# RTS5921 register map
Vendor: Realtek Semiconductor Corp.; Series: RTS5921 Series; File version: 0.01
CPU: ARMV8MBL r0p0, little endian, MPU, no FPU, VTOR, 3 interrupt priority bits
Registers are 32-bit, read-write, reset 0x0 unless marked. A register's access mark holds for its fields unless they carry their own. Offsets are from the block's base; [hi:lo] are bit positions; {n}, {i} and the like mark numbered series; 'fields as' and 'values as' point back to an identical list.

## USB_CORE — USB OTG Controller
Base 0x40040000
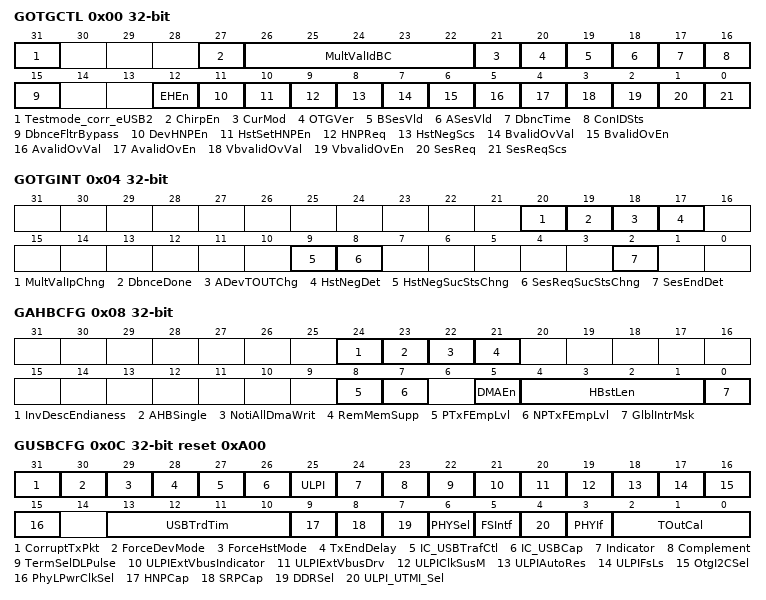
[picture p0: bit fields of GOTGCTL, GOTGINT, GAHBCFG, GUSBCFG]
0x00 GOTGCTL — Control and Status Register
  [31] Testmode_corr_eUSB2 — Correction for eUSB2 PHY during Test mode
  [27] ChirpEn — Core asserting chirp_on before sending an actual Chirp K signal on USB.
  [26:22] MultValIdBC ro — Multi Valued ID pin (MultValIdBC)
  [21] CurMod ro — Current Mode of Operation
  [20] OTGVer — OTG Version
  [19] BSesVld ro — B-session Valid
  [18] ASesVld ro — A-session Valid
  [17] DbncTime ro — Debounce Time
  [16] ConIDSts ro — Connector ID Status
  [15] DbnceFltrBypass — Debounce Filter Bypass
  [12] EHEn — Embedded Host Enable (EHEn)
  [11] DevHNPEn — Device HNP Enabled (DevHNPEn)
  [10] HstSetHNPEn — Host Set HNP Enable (HstSetHNPEn)
  [9] HNPReq — HNP Request (HNPReq)
  [8] HstNegScs ro — Host Negotiation Success (HstNegScs)
  [7] BvalidOvVal — B-Peripheral Session Valid OverrideValue (BvalidOvVal)
  [6] BvalidOvEn — B-Peripheral Session Valid Override Enable
  [5] AvalidOvVal — A-Peripheral Session Valid OverrideValue (AvalidOvVal)
  [4] AvalidOvEn — A-Peripheral Session Valid Override Enable
  [3] VbvalidOvVal — VBUS Valid OverrideValue (VbvalidOvVal)
  [2] VbvalidOvEn — VBUS Valid Override Enable
  [1] SesReq — Session Request
  [0] SesReqScs ro — Session Request Success
0x04 GOTGINT — Interrupt Register
  [20] MultValIpChng — Indicates change in ACA pin value
    0=NO_ACA_PIN_CHANGE (No change in ACA pin value); 1=ACA_PIN_CHANGE (Change in ACA pin value)
  [19] DbnceDone — Debounce Done
    0=INACTIVE (Waiting for debounce completion); 1=ACTIVE (Debounce completed)
  [18] ADevTOUTChg — A-Device Timeout Change
    0=INACTIVE (No A-Device Timeout); 1=ACTIVE (A-Device Timeout)
  [17] HstNegDet — Host Negotiation Detected
    0=INACTIVE (No Active HNP Request); 1=ACTIVE (Active HNP Request Detected)
  [9] HstNegSucStsChng — Host Negotiation Success Status Change
    0=INACTIVE (No Change); 1=ACTIVE (Host Negotiation Status Change)
  [8] SesReqSucStsChng — Session Request Success Status Change
    0=INACTIVE (No Change in Session Request Status); 1=ACTIVE (Session Request Status has changed)
  [2] SesEndDet — Session End Detected
    0=INACTIVE (Session is Active); 1=ACTIVE (Session End signal is deasserted)
0x08 GAHBCFG — AHB Configuration Register
  [24] InvDescEndianess — Invert Descriptor Endianess
    0=DISABLE (Descriptor Endianness is same as AHB Master Endianness); 1=ENABLE (Descriptor Endianness is opposite to AHB Master Endianness)
  [23] AHBSingle — AHB Single Support
    0=INCRBURST (INCR burst size); 1=SINGLEBURST (Single burst size)
  [22] NotiAllDmaWrit — Notify All DMA Write Transactions
    0=LASTTRANS; 1=ALLTRANS
  [21] RemMemSupp — Remote Memory Support
    0=DISABLED; 1=ENABLED
  [8] PTxFEmpLvl — Periodic TxFIFO Empty Level
    0=HALFEMPTY; 1=EMPTY
  [7] NPTxFEmpLvl — Non-Periodic TxFIFO Empty Level
    0=HALFEMPTY; 1=EMPTY
  [5] DMAEn — DMA Enable
    0=SLAVEMODE; 1=DMAMODE
  [4:1] HBstLen — Burst Length/Type
    0=WORD1ORSINGLE; 1=WORD4ORINCR; 2=WORD8; 3=WORD16ORINCR4; 4=WORD32; 5=WORD64ORINCR8; 6=WORD128; 7=WORD256ORINCR16; 8=WORDX (Others reserved)
  [0] GlblIntrMsk — Global Interrupt Mask
    0=MASK (Mask the interrupt assertion to the application); 1=NOMASK (Unmask the interrupt assertion to the application)
0x0C GUSBCFG reset 0xA00 — USB Configuration Register
  [31] CorruptTxPkt — Corrupt Tx packet
    0=NODEBUG (Normal Mode); 1=DEBUG (Debug Mode)
  [30] ForceDevMode — Force Device Mode
    0=DISABLED (Normal Mode); 1=ENABLED (Force Device Mode)
  [29] ForceHstMode — Force Host Mode
    0=DISABLED (Normal Mode); 1=ENABLED (Force Host Mode)
  [28] TxEndDelay
    0=DISABLED (Normal Mode); 1=ENABLED (Tx End delay)
  [27] IC_USBTrafCtl — IC_USB-TrafficPullRemove Control
    0=DISABLED (Not detached during signaling); 1=ENABLED (Detached during signaling)
  [26] IC_USBCap — IC_USB-Capable PHY Interface Selection
    0=NOTSELECTED (PHY Interface not selected); 1=SELECTED (PHY Interface selected)
  [25] ULPI — ULPI Interface Protect Disable
    0=ENABLED (Interface protect circuit enabled); 1=DISABLED (Interface protect circuit disabled)
  [24] Indicator — Indicator Pass Through
    0=QUALIFIED (Qualified with Internal VbusValid); 1=NOTQUALIFIED (Not qualified with Internal VbusValid)
  [23] Complement — Indicator Complement Controls
    0=NONINVERT (Does not invert signal); 1=INVERT (Inverts the signal)
  [22] TermSelDLPulse — TermSel DLine Pulsing Selection
    0=TXVALID (Using utmi_txvalid); 1=TERMSEL (Using utmi_termsel)
  [21] ULPIExtVbusIndicator — ULPI External VBUS Indicator
    0=INTERN (Uses internal VBUS comparator); 1=EXTERN (Uses external VBUS comparator)
  [20] ULPIExtVbusDrv — ULPI External VBUS Drive
    0=INTERN (Drives VBUS with internal charge pump); 1=EXTERN (Drives VBUS using external supply)
  [19] ULPIClkSusM — ULPI Clock SuspendM
    0=PWDCLK (Powers down internal clock during suspend); 1=NONPWDCLK (Does not power down internal clock)
  [18] ULPIAutoRes — ULPI Auto Resume
    0=DISABLED (No AutoResume feature); 1=ENABLED (Uses AutoResume feature)
  [17] ULPIFsLs — ULPI FS/LS Select
    0=DISABLED (ULPI interface selected); 1=ENABLED (ULPI FS/LS serial interface selected)
  [16] OtgI2CSel — UTMIFS or I2C Interface Select
    0=DISABLED (UTMI+ USB 1.1 interface for OTG signals); 1=ENABLED (I2C interface for OTG signals)
  [15] PhyLPwrClkSel — PHY Low-Power Clock Select
    0=INTPLLCLK (480-MHz Internal PLL clock); 1=EXTCLK (48-MHz External Clock)
  [13:10] USBTrdTim — USB Turnaround Time
    9=TURNTIME8BIT (8-bit UTMI+); 5=TURNTIME16BIT (16-bit UTMI+)
  [9] HNPCap — HNP-Capable
    0=DISABLED (HNP not enabled); 1=ENABLED (HNP capability enabled)
  [8] SRPCap — SRP-Capable
    0=DISABLED (SRP capability not enabled); 1=ENABLED (SRP capability enabled)
  [7] DDRSel — ULPI DDR Select
    0=SDR (SDR ULPI Interface); 1=DDR (DDR ULPI Interface)
  [6] PHYSel — PHY Selection
    0=USB20 (Use USB 2.0 high-speed UTMI+ or ULPI PHY); 1=USB11 (USB 1.1 full-speed serial transceiver selected)
  [5] FSIntf — Full-Speed Serial Interface Select
    0=FS6PIN (6-pin unidirectional interface); 1=FS3PIN (3-pin bidirectional interface)
  [4] ULPI_UTMI_Sel — ULPI or UTMI+ Select
    0=UTMI (UTMI+ Interface); 1=ULPI (ULPI Interface)
  [3] PHYIf — PHY Interface
    0=BITS8 (8bit Mode); 1=BITS16 (16bit Mode)
  [2:0] TOutCal — HS/FS Timeout Calibration
    0=ZERO (Add 0 PHY clocks); 1=ONE (Add 1 PHY clocks); 2=TWO (Add 2 PHY clocks); 3=THREE (Add 3 PHY clocks); 4=FOUR (Add 4 PHY clocks); 5=FIVE (Add 5 PHY clocks); 6=SIX (Add 6 PHY clocks); 7=SEVEN (Add 7 PHY clocks)
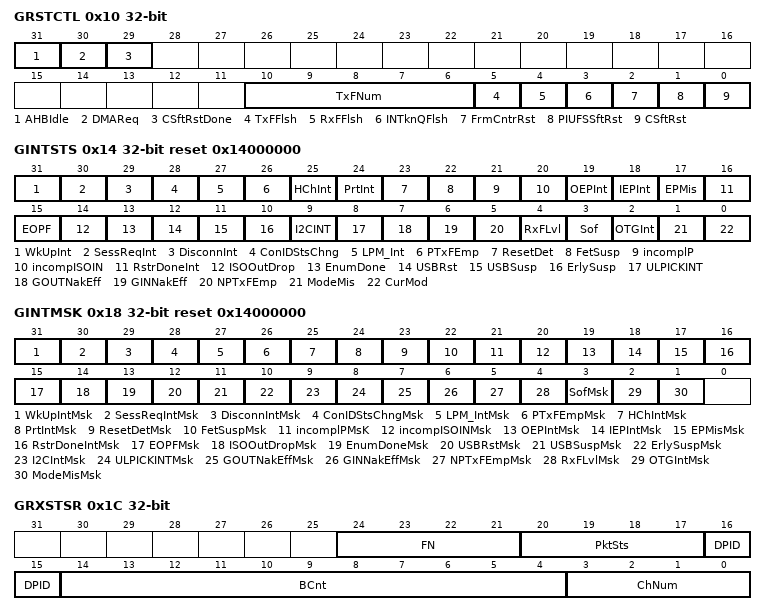
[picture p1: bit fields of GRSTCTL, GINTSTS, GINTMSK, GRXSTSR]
0x10 GRSTCTL — Reset Register
  [31] AHBIdle ro — AHB Master Idle
    0=INACTIVE (Not Idle); 1=ACTIVE (AHB Master Idle)
  [30] DMAReq ro — DMA Request Signal
    0=INACTIVE (No DMA request); 1=ACTIVE (DMA request in progress)
  [29] CSftRstDone — Core Soft Reset Done
    0=INACTIVE (No reset); 1=ACTIVE (Core Soft Reset is done)
  [10:6] TxFNum — TxFIFO Number
    0=TXF0 (Periodic TxFIFO 0 Flush); 1=TXF1 (Periodic TxFIFO 1 Flush); 2=TXF2 (Periodic TxFIFO 2 Flush); 16=TXF16 (Flush all Tx FIFOs)
  [5] TxFFlsh — TxFIFO Flush
    0=INACTIVE (No Flush); 1=ACTIVE (Flushes TxFIFOs)
  [4] RxFFlsh — RxFIFO Flush
    0=INACTIVE (Does not flush RxFIFO); 1=ACTIVE (Flushes entire RxFIFO)
  [3] INTknQFlsh — IN Token Queue Flush
    0=INACTIVE (No Flush); 1=ACTIVE (Flush IN Token Queue)
  [2] FrmCntrRst — Host Frame Counter Reset
    0=NOTACTIVE (No reset); 1=ACTIVE (Reset Frame Counter)
  [1] PIUFSSftRst — PIU FS Soft Reset
    0=RESET_INACTIVE (No Reset); 1=RESET_ACTIVE (PIU FS Soft Reset)
  [0] CSftRst — Core Soft Reset
    0=NOTACTIVE (No reset); 1=ACTIVE (Reset both hclk and phy_clock domains)
0x14 GINTSTS reset 0x14000000 — Interrupt Register
  [31] WkUpInt — Resume/Remote Wakeup Detected Interrupt
    0=INACTIVE (Not active); 1=ACTIVE (Resume/Remote Wakeup Detected)
  [30] SessReqInt — Session Request/New Session Detected Interrupt
    0=INACTIVE (Not active); 1=ACTIVE (Session Request/New Session Detected)
  [29] DisconnInt — Disconnect Detected Interrupt
    0=INACTIVE (Not active); 1=ACTIVE (Disconnect Detected)
  [28] ConIDStsChng — Connector ID Status Change
    0=INACTIVE (Not active); 1=ACTIVE (Connector ID Status Change)
  [27] LPM_Int — LPM Transaction Received Interrupt
    0=INACTIVE (Not active); 1=ACTIVE (LPM Transaction Received)
  [26] PTxFEmp ro — Periodic TxFIFO Empty
    0=INACTIVE (Not active); 1=ACTIVE (Periodic TxFIFO Empty)
  [25] HChInt ro — Host Channels Interrupt
    0=INACTIVE (Not active); 1=ACTIVE (Host Channels Interrupt)
  [24] PrtInt ro — Host Port Interrupt
    0=INACTIVE (Not active); 1=ACTIVE (Host Port Interrupt)
  [23] ResetDet — Reset Detected Interrupt
    0=INACTIVE (Not active); 1=ACTIVE (Reset Detected)
  [22] FetSusp — Data Fetch Suspended
    0=INACTIVE (Not active); 1=ACTIVE (Data Fetch Suspended)
  [21] incomplP — Incomplete Periodic Transfer
    0=INACTIVE (Not active); 1=ACTIVE (Incomplete Periodic Transfer)
  [20] incompISOIN — Incomplete Isochronous IN Transfer
    0=INACTIVE (Not active); 1=ACTIVE (Incomplete Isochronous IN Transfer)
  [19] OEPInt ro — OUT Endpoints Interrupt
    0=INACTIVE (Not active); 1=ACTIVE (OUT Endpoints Interrupt)
  [18] IEPInt ro — IN Endpoints Interrupt
    0=INACTIVE (Not active); 1=ACTIVE (IN Endpoints Interrupt)
  [17] EPMis — Endpoint Mismatch Interrupt
    0=INACTIVE (Not active); 1=ACTIVE (Endpoint Mismatch Interrupt)
  [16] RstrDoneInt — Restore Done Interrupt
    0=INACTIVE (Not active); 1=ACTIVE (Restore Done Interrupt)
  [15] EOPF — End of Periodic Frame Interrupt
    0=INACTIVE (Not active); 1=ACTIVE (End of Periodic Frame Interrupt)
  [14] ISOOutDrop — Isochronous OUT Packet Dropped Interrupt
    0=INACTIVE (Not active); 1=ACTIVE (Isochronous OUT Packet Dropped)
  [13] EnumDone — Enumeration Done
    0=INACTIVE (Not active); 1=ACTIVE (Enumeration Done)
  [12] USBRst — USB Reset
    0=INACTIVE (Not active); 1=ACTIVE (USB Reset)
  [11] USBSusp — USB Suspend
    0=INACTIVE (Not active); 1=ACTIVE (USB Suspend)
  [10] ErlySusp — Early Suspend
    0=INACTIVE (No Idle state detected); 1=ACTIVE (3ms of Idle state detected)
  [9] I2CINT — I2C Interrupt
    0=INACTIVE (Not Active); 1=ACTIVE (I2C Interrupt)
  [8] ULPICKINT — ULPI Carkit Interrupt
    0=INACTIVE (Not Active); 1=ACTIVE (Interrupt is asserted high when ULPI Carkit Interrupt is received)
  [7] GOUTNakEff ro — Global OUT NAK Effective
    0=INACTIVE (Not Active); 1=ACTIVE (Global OUT NAK Effective)
  [6] GINNakEff ro — Global IN Non-periodic NAK Effective
    0=INACTIVE (Global Non-periodic IN NAK not active); 1=ACTIVE (Set Global Non-periodic IN NAK bit)
  [5] NPTxFEmp ro — Non-periodic TxFIFO Empty
    0=INACTIVE (Non-periodic TxFIFO is not empty); 1=ACTIVE (Non-periodic TxFIFO is empty)
  [4] RxFLvl ro — RxFIFO Non-Empty
    0=INACTIVE (RxFIFO is empty); 1=ACTIVE (RxFIFO is not empty)
  [3] Sof — Start of (micro)Frame
    0=INACTIVE (No Start of Frame); 1=ACTIVE (Start of Frame)
  [2] OTGInt ro — OTG Interrupt
    0=INACTIVE (No Interrupt); 1=ACTIVE (OTG Interrupt)
  [1] ModeMis — Mode Mismatch Interrupt
    0=INACTIVE (No Mode Mismatch Interrupt); 1=ACTIVE (Mode Mismatch Interrupt)
  [0] CurMod ro — Current Mode of Operation
    0=DEVICE (Device mode); 1=HOST (Host mode)
0x18 GINTMSK reset 0x14000000 — Interrupt Mask Register
  [31] WkUpIntMsk — Resume/Remote Wakeup Detected Interrupt Mask
    0=MASK (Mask Resume/Remote Wakeup Detected Interrupt); 1=NOMASK (Unmask Resume/Remote Wakeup Detected Interrupt)
  [30] SessReqIntMsk — Session Request/New Session Detected Interrupt Mask
    0=MASK (Mask Session Request/New Session Detected Interrupt); 1=NOMASK (Unmask Session Request/New Session Detected Interrupt)
  [29] DisconnIntMsk — Disconnect Detected Interrupt Mask
    0=MASK (Mask Disconnect Detected Interrupt); 1=NOMASK (Unmask Disconnect Detected Interrupt)
  [28] ConIDStsChngMsk — Connector ID Status Change Mask
    0=MASK (Mask Connector ID Status Change Interrupt); 1=NOMASK (Unmask Connector ID Status Change Interrupt)
  [27] LPM_IntMsk — LPM Transaction Received Interrupt Mask
    0=MASK (Mask LPM Transaction Received Interrupt); 1=NOMASK (Unmask LPM Transaction Received Interrupt)
  [26] PTxFEmpMsk — Periodic TxFIFO Empty Mask, Host only
    0=MASK (Mask Periodic TxFIFO Empty Interrupt); 1=NOMASK (Unmask Periodic TxFIFO Empty Interrupt)
  [25] HChIntMsk — Host Channels Interrupt Mask, Host only
    0=MASK (Mask Host Channels Interrupt); 1=NOMASK (Unmask Host Channels Interrupt)
  [24] PrtIntMsk — Host Port Interrupt Mask, Host only
    0=MASK (Mask Host Port Interrupt); 1=NOMASK (Unmask Host Port Interrupt)
  [23] ResetDetMsk — Reset Detected Interrupt Mask, Device only
    0=MASK (Mask Reset Detected Interrupt); 1=NOMASK (Unmask Reset Detected Interrupt)
  [22] FetSuspMsk — Data Fetch Suspended Mask, Device only
    0=MASK (Mask Data Fetch Suspended Interrupt); 1=NOMASK (Unmask Data Fetch Suspended Interrupt)
  [21] incomplPMsK — Incomplete Periodic Transfer Mask, Host only
    0=MASK (Mask Incomplete Periodic Transfer Interrupt); 1=NOMASK (Unmask Incomplete Periodic Transfer Interrupt)
  [20] incompISOINMsk — Incomplete Isochronous IN Transfer Mask, Device only
    0=MASK (Mask Incomplete Isochronous IN Transfer Interrupt); 1=NOMASK (Unmask Incomplete Isochronous IN Transfer Interrupt)
  [19] OEPIntMsk — OUT Endpoints Interrupt Mask, Device only
    0=MASK (Mask OUT Endpoints Interrupt); 1=NOMASK (Unmask OUT Endpoints Interrupt)
  [18] IEPIntMsk — IN Endpoints Interrupt Mask, Device only
    0=MASK (Mask IN Endpoints Interrupt); 1=NOMASK (Unmask IN Endpoints Interrupt)
  [17] EPMisMsk — Endpoint Mismatch Interrupt Mask, Device only
    0=MASK (Mask Endpoint Mismatch Interrupt); 1=NOMASK (Unmask Endpoint Mismatch Interrupt)
  [16] RstrDoneIntMsk — Restore Done Interrupt Mask
    0=MASK (Mask Restore Done Interrupt); 1=NOMASK (Unmask Restore Done Interrupt)
  [15] EOPFMsk — End of Periodic Frame Interrupt Mask, Device only
    0=MASK (Mask End of Periodic Frame Interrupt); 1=NOMASK (Unmask End of Periodic Frame Interrupt)
  [14] ISOOutDropMsk — Isochronous OUT Packet Dropped Interrupt Mask, Device only
    0=MASK (Mask Isochronous OUT Packet Dropped Interrupt); 1=NOMASK (Unmask Isochronous OUT Packet Dropped Interrupt)
  [13] EnumDoneMsk — Enumeration Done Mask, Device only
    0=MASK (Mask Enumeration Done Interrupt); 1=NOMASK (Unmask Enumeration Done Interrupt)
  [12] USBRstMsk — USB Reset Mask, Device only
    0=MASK (Mask USB Reset Interrupt); 1=NOMASK (Unmask USB Reset Interrupt)
  [11] USBSuspMsk — USB Suspend Mask, Device only
    0=MASK (Mask USB Suspend Interrupt); 1=NOMASK (Unmask USB Suspend Interrupt)
  [10] ErlySuspMsk — Early Suspend Mask, Device only
    0=MASK (Mask Early Suspend Interrupt); 1=NOMASK (Unmask Early Suspend Interrupt)
  [9] I2CIntMsk — I2C Interrupt Mask
    0=MASK (Mask I2C Interrupt); 1=NOMASK (Unmask I2C Interrupt)
  [8] ULPICKINTMsk — ULPI Carkit Interrupt Mask
    0=MASK (Mask ULPI Carkit Interrupt); 1=NOMASK (Unmask ULPI Carkit Interrupt)
  [7] GOUTNakEffMsk — Global OUT NAK Effective Mask, Device only
    0=MASK (Mask Global OUT NAK Effective Interrupt); 1=NOMASK (Unmask Global OUT NAK Effective Interrupt)
  [6] GINNakEffMsk — Global Non-periodic IN NAK Effective Mask, Device only
    0=MASK (Mask Global Non-periodic IN NAK Effective Interrupt); 1=NOMASK (Unmask Global Non-periodic IN NAK Effective Interrupt)
  [5] NPTxFEmpMsk — Non-periodic TxFIFO Empty Mask
    0=MASK (Mask Non-periodic TxFIFO Empty Interrupt); 1=NOMASK (Unmask Non-periodic TxFIFO Empty Interrupt)
  [4] RxFLvlMsk — Receive FIFO Non-Empty Mask
    0=MASK (Mask Receive FIFO Non-Empty Interrupt); 1=NOMASK (Unmask Receive FIFO Non-Empty Interrupt)
  [3] SofMsk — Start of Frame Mask
    0=MASK (Mask Start of Frame Interrupt); 1=NOMASK (Unmask Start of Frame Interrupt)
  [2] OTGIntMsk — OTG Interrupt Mask
    0=MASK (Mask OTG Interrupt); 1=NOMASK (Unmask OTG Interrupt)
  [1] ModeMisMsk — Mode Mismatch Interrupt Mask
    0=MASK (Mask Mode Mismatch Interrupt); 1=NOMASK (Unmask Mode Mismatch Interrupt)
0x1C GRXSTSR ro — Receive Status Debug Read Register
  [24:21] FN — Frame Number (Device only)
  [20:17] PktSts — Packet Status
    1=OUTNAK (Global OUT NAK in device mode); 2=INOUTDPRX (IN/OUT data packet received); 3=INOUTTRCOM (IN or OUT transfer completed); 4=DSETUPCOM (SETUP transaction completed); 5=DTTOG (Data toggle error); 6=DSETUPRX (SETUP data packet received); 7=CHHALT (Channel halted)
  [16:15] DPID — Data PID
    0=DATA0 (DATA0 packet); 2=DATA1 (DATA1 packet); 1=DATA2 (DATA2 packet); 3=MDATA (MDATA packet)
  [14:4] BCnt — Byte Count
  [3:0] ChNum — Channel Number / Endpoint Number
    {v}=CHEP{v} (Channel or Endpoint {v}) (v=0..15)
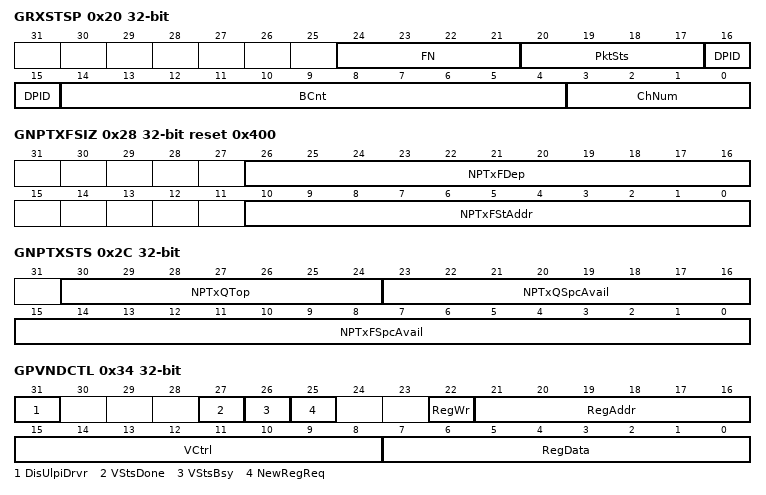
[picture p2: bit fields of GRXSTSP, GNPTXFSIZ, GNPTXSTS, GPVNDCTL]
0x20 GRXSTSP ro — Receive Status Read/Pop Register
  fields as GRXSTSR
0x24 GRXFSIZ reset 0x200 — Receive FIFO Size Register
0x28 GNPTXFSIZ reset 0x400 — Non-periodic Transmit FIFO Size Register
  [26:16] NPTxFDep — Non-periodic TxFIFO Depth
  [10:0] NPTxFStAddr — Non-periodic Transmit RAM Start Address
0x2C GNPTXSTS ro — Non-periodic Transmit FIFO/Queue Status Register
  [30:24] NPTxQTop — Top of the Non-periodic Transmit Request Queue
  [23:16] NPTxQSpcAvail — Non-periodic Transmit Request Queue Space Available
  [15:0] NPTxFSpcAvail — Non-periodic TxFIFO Space Available
0x30 GI2CCTL — I2C Access Register
0x34 GPVNDCTL — PHY Vendor Control Register
  [31] DisUlpiDrvr — Disable ULPI Drivers
    0=ENABLED (Enable ULPI output signals); 1=DISABLED (Disable ULPI output signals)
  [27] VStsDone — VStatus Done
    0=INACTIVE (VStatus Done inactive); 1=ACTIVE (VStatus Done active)
  [26] VStsBsy ro — VStatus Busy
    0=INACTIVE (VStatus Busy inactive); 1=ACTIVE (VStatus Busy active)
  [25] NewRegReq — New Register Request
    0=INACTIVE (New Register Request not active); 1=ACTIVE (New Register Request active)
  [22] RegWr — Register Write
    0=READ; 1=WRITE
  [21:16] RegAddr — Register Address
  [15:8] VCtrl — UTMI+ Vendor Control Register Address
  [7:0] RegData — Register Data
0x38 GGPIO — General Purpose Input/Output Register
0x3C GUID — User ID Register
0x40 GSNPSID ro — Synopsys ID Register
0x44 GHWCFG1 ro — User Hardware Configuration 1 Register
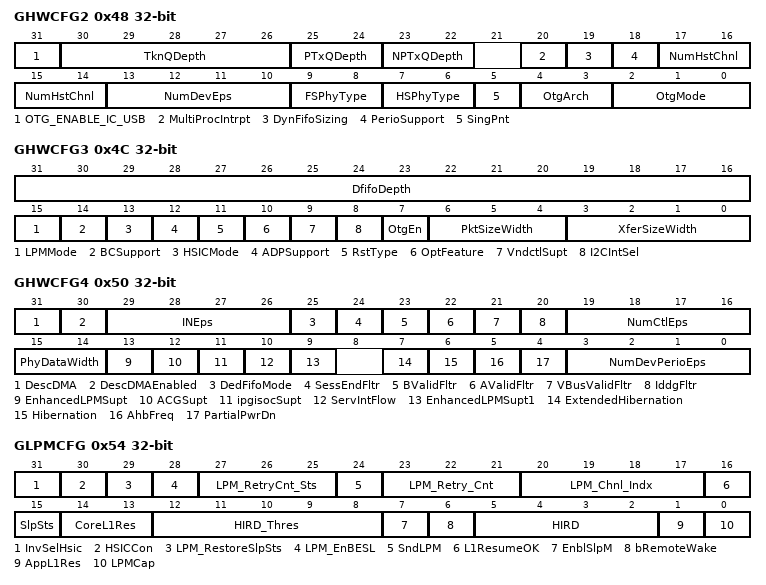
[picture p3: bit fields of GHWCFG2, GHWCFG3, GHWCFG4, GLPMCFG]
0x48 GHWCFG2 ro — User Hardware Configuration 2 Register
  [31] OTG_ENABLE_IC_USB — IC_USB mode specified for mode of operation
    0=DISABLE (Disabled the IC_USB Full-Speed Serial Transceiver interface); 1=ENABLE (Enabled the IC_USB Full-Speed Serial Transceiver interface)
  [30:26] TknQDepth — Device Mode IN Token Sequence Learning Queue Depth
  [25:24] PTxQDepth — Host Mode Periodic Request Queue Depth
    0=QUE2 (Queue Depth 2); 1=QUE4 (Queue Depth 4); 2=QUE8 (Queue Depth 8); 3=QUE16 (Queue Depth 16)
  [23:22] NPTxQDepth — Non-periodic Request Queue Depth
    0=TWO (Queue size 2); 1=FOUR (Queue size 4); 2=EIGHT (Queue size 8)
  [20] MultiProcIntrpt — Multi Processor Interrupt Enabled
    0=DISABLED (No Multi Processor Interrupt Enabled); 1=ENABLED (Multi Processor Interrupt Enabled)
  [19] DynFifoSizing — Dynamic FIFO Sizing Enabled
    0=DISABLED (Dynamic FIFO Sizing Disabled); 1=ENABLED (Dynamic FIFO Sizing Enabled)
  [18] PerioSupport — Periodic OUT Channels Supported in Host Mode
    0=DISABLED (Periodic OUT Channels is not supported in Host Mode); 1=ENABLED (Periodic OUT Channels Supported in Host Mode Supported)
  [17:14] NumHstChnl — Number of Host Channels
    {v}=HOSTCH{v} (Host Channel {v+1}) (v=0..15)
  [13:10] NumDevEps — Number of Device Endpoints
    {v}=ENDPT{v} (End point {v}) (v=0..15)
  [9:8] FSPhyType — Full-Speed PHY Interface Type
    0=NO_FS (Full-speed interface not supported); 1=FS (Dedicated full-speed interface is supported); 2=FSPLUSUTMI (FS pins shared with UTMI+ pins is supported); 3=FSPLUSULPI (FS pins shared with ULPI pins is supported)
  [7:6] HSPhyType — High-Speed PHY Interface Type
    0=NOHS (High-Speed interface not supported); 1=UTMIPLUS (High Speed Interface UTMI+ is supported); 2=ULPI (High Speed Interface ULPI is supported); 3=UTMIPUSULPI (High Speed Interfaces UTMI+ and ULPI is supported)
  [5] SingPnt — Point-to-Point
    0=MULTIPOINT (Multi-point application (hub and split support)); 1=SINGLEPOINT (Single-point application (no hub and split support))
  [4:3] OtgArch — Architecture
    0=SLAVEMODE; 1=EXTERNALDMA (External DMA Mode); 2=INTERNALDMA (Internal DMA Mode)
  [2:0] OtgMode — Mode of Operation
    0=HNPSRP (HNP- and SRP-Capable OTG (Host and Device)); 1=SRPOTG (SRP-Capable OTG (Host and Device)); 2=NHNPNSRP (Non-HNP and Non-SRP Capable OTG (Host and Device)); 3=SRPCAPD (SRP-Capable Device); 4=NONOTGD (Non-OTG Device); 5=SRPCAPH (SRP-Capable Host); 6=NONOTGH (Non-OTG Host)
0x4C GHWCFG3 ro — User Hardware Configuration 3 Register
  [31:16] DfifoDepth
  [15] LPMMode
    0=DISABLED (LPM disabled); 1=ENABLED (LPM enabled)
  [14] BCSupport — Battery Charger Support
    0=DISABLED (No Battery Charger Support); 1=ENABLED (Battery Charger Support present)
  [13] HSICMode
    0=DISABLED (No HSIC capability); 1=ENABLED (HSIC-capable with shared UTMI PHY)
  [12] ADPSupport — ADP Logic Support
    0=DISABLED (ADP logic is not present); 1=ENABLED (ADP logic is present)
  [11] RstType — Reset Style for Clocked Blocks
    0=ASYNCRST (Asynchronous reset is used); 1=SYNCRST (Synchronous reset is used)
  [10] OptFeature — Optional Features Removed
    0=DISABLED (Optional features not removed); 1=ENABLED (Optional features removed)
  [9] VndctlSupt — Vendor Control Interface Support
    0=DISABLED (Vendor Control Interface not available); 1=ENABLED (Vendor Control Interface available)
  [8] I2CIntSel — I2C Interface Selection
    0=DISABLED (I2C Interface not available); 1=ENABLED (I2C Interface available)
  [7] OtgEn — OTG Function Enabled
    0=DISABLED (Not OTG Capable); 1=ENABLED (OTG Capable)
  [6:4] PktSizeWidth — Width of Packet Size Counters
    {v}=BITS{v+4} (Width of Packet Size Counter {v+4}) (v=0..6)
  [3:0] XferSizeWidth — Width of Transfer Size Counters
    {v}=WIDTH{v+11} (Width of Transfer Size Counter {v+11} bits) (v=0..8)
0x50 GHWCFG4 ro — User Hardware Configuration 4 Register
  [31] DescDMA — Scatter/Gather DMA configuration
    0=CONFIG1 (Non-Dynamic configuration); 1=CONFIG2 (Dynamic configuration)
  [30] DescDMAEnabled — Scatter/Gather DMA configuration enabled
    0=DISABLE (Non-Scatter/Gather DMA configuration); 1=ENABLE (Scatter/Gather DMA configuration)
  [29:26] INEps — Number of Device Mode IN Endpoints Including Control Endpoints
    0=ENDPT1 (1 IN Endpoint); 1=ENDPT2 (2 IN Endpoints); 15=ENDPT16 (16 IN Endpoints)
  [25] DedFifoMode — Enable Dedicated Transmit FIFO for device IN Endpoints
    0=DISABLED (Dedicated Transmit FIFO Operation not enabled); 1=ENABLED (Dedicated Transmit FIFO Operation enabled)
  [24] SessEndFltr — Session end filter enabled
    0=DISABLED (No filter); 1=ENABLED (Filter enabled)
  [23] BValidFltr — b_valid filter enabled
    0=DISABLED (No Filter); 1=ENABLED (Filter enabled)
  [22] AValidFltr — a_valid filter enabled
    0=DISABLED (No filter); 1=ENABLED (Filter enabled)
  [21] VBusValidFltr — VBUS Valid Filter Enabled
    0=DISABLED (Vbus Valid Filter Disabled); 1=ENABLED (Vbus Valid Filter Enabled)
  [20] IddgFltr — IDDIG Filter Enabled
    0=DISABLED (Iddig Filter Disabled); 1=ENABLED (Iddig Filter Enabled)
  [19:16] NumCtlEps — Number of Device Mode Control Endpoints in Addition to Endpoint 0
    0=ENDPT0 (End point 0); 1=ENDPT1 (End point 1); 15=ENDPT15 (End point 15)
  [15:14] PhyDataWidth — UTMI+ PHY/ULPI-to-Internal UTMI+ Wrapper Data Width
    0=WIDTH1 (8 bits); 1=WIDTH2 (16 bits); 2=WIDTH3 (8/16 bits, software selectable)
  [13] EnhancedLPMSupt — Enhanced LPM Support
    0=DISABLED (Enhanced LPM Support is Disabled); 1=ENABLED (Enhanced LPM Support is enabled)
  [12] ACGSupt — Active Clock Gating Support
    0=DISABLED (Active Clock Gating Support disabled); 1=ENABLED (Active Clock Gating Support enabled)
  [11] ipgisocSupt — Interpacket Gap ISOC OUT Worst-case Support
    0=DISABLED (Interpacket Gap ISOC OUT Worst-case Support is Disabled); 1=ENABLED (Interpacket Gap ISOC OUT Worst-case Support is Enabled)
  [10] ServIntFlow — Service Interval Flow
    0=DISABLED (Service Interval Flow not supported); 1=ENABLED (Service Interval Flow supported)
  [9] EnhancedLPMSupt1 — Enhanced LPM Support1
    0=DISABLED (Reject L1 Request if Non-Periodic TxFIFO is not empty); 1=ENABLED (Accept L1 Request even if Non-Periodic TxFIFO not empty)
  [7] ExtendedHibernation — Enable Hibernation
    0=DISABLED (Extended Hibernation feature not enabled); 1=ENABLED (Extended Hibernation feature enabled)
  [6] Hibernation — Enable Hibernation
    0=DISABLED (Hibernation feature disabled); 1=ENABLED (Hibernation feature enabled)
  [5] AhbFreq — Minimum AHB Frequency Less Than 60 MHz
    0=DISABLED (Minimum AHB Frequency More Than 60 MHz); 1=ENABLED (Minimum AHB Frequency Less Than 60 MHz)
  [4] PartialPwrDn — Enable Partial Power Down
    0=DISABLED (Partial Power Down disabled); 1=ENABLED (Partial Power Down enabled)
  [3:0] NumDevPerioEps — Number of Device Mode Periodic IN Endpoints
    0=Number of Periodic IN EPs is 0; 1=Number of Periodic IN EPs is 1; 15=Number of Periodic IN EPs is 15
0x54 GLPMCFG — LPM Config Register
  [31] InvSelHsic — HSIC-Invert Select HSIC
    0=HSIC capability enabled if if_sel_hsic=1; 1=HSIC capability enabled if if_sel_hsic=0
  [30] HSICCon — HSIC-Connect
    0=DISABLE_HSIC_CONNECT (Core does not initiate HSIC connect); 1=ENABLE_HSIC_CONNECT (Core initiates the HSIC connect)
  [29] LPM_RestoreSlpSts — LPM Restore Sleep Status
    0=DISABLED (Shallow Sleep mode based on BESL value); 1=ENABLED (Deep Sleep mode based on BESL value)
  [28] LPM_EnBESL — LPM Enable BESL
    0=DISABLED (BESL is disabled); 1=ENABLED (BESL is enabled)
  [27:25] LPM_RetryCnt_Sts ro — LPM Retry Count Status
    0=RETRY_REM0 (Zero LPM retries remaining); 1=RETRY_REM1 (One LPM retry remaining); 2=RETRY_REM2 (Two LPM retries remaining); 3=RETRY_REM3 (Three LPM retries remaining); 4=RETRY_REM4 (Four LPM retries remaining); 5=RETRY_REM5 (Five LPM retries remaining); 6=RETRY_REM6 (Six LPM retries remaining); 7=RETRY_REM7 (Seven LPM retries remaining)
  [24] SndLPM — Send LPM Transaction
    0=DISABLED (Received the response from device); 1=ENABLED (Sending LPM transaction)
  [23:21] LPM_Retry_Cnt — LPM Retry Count
    0=RETRY0 (Zero LPM retries); 1=RETRY1 (One LPM retry); 2=RETRY2 (Two LPM retries); 3=RETRY3 (Three LPM retries); 4=RETRY4 (Four LPM retries); 5=RETRY5 (Five LPM retries); 6=RETRY6 (Six LPM retries); 7=RETRY7 (Seven LPM retries)
  [20:17] LPM_Chnl_Indx — LPM Channel Index
    {v}=CH{v} (Channel {v}) (v=0..15)
  [16] L1ResumeOK — Sleep State Resume OK
    0=NOTOK (Cannot start Resume from Sleep state); 1=OK (Can start Resume from Sleep state)
  [15] SlpSts — Port Sleep Status
    0=CORE_NOT_IN_L1 (Core is not in L1); 1=CORE_IN_L1 (Core transitions to Sleep state)
  [14:13] CoreL1Res — LPM Response
    0=LPMRESP1 (No handshake response); 1=LPMRESP2 (STALL response); 2=LPMRESP3 (NYET response); 3=LPMRESP4 (ACK response)
  [12:8] HIRD_Thres — BESL/HIRD Threshold
  [7] EnblSlpM — Enable utmi_sleep_n
    0=DISABLED (utmi_sleep_n assertion not transferred); 1=ENABLED (utmi_sleep_n assertion transferred)
  [6] bRemoteWake — RemoteWakeEnable
    0=DISABLED (Remote Wakeup is disabled); 1=ENABLED (Remote Wakeup enabled)
  [5:2] HIRD — Host-Initiated Resume Duration
  [1] AppL1Res — LPM response programmed by application
    0=NYET_RESP (Respond with NYET on error detection); 1=ACK_RESP (Respond with ACK on successful LPM transaction)
  [0] LPMCap — LPM-Capable
    0=DISABLED (LPM capability not enabled); 1=ENABLED (LPM capability enabled)
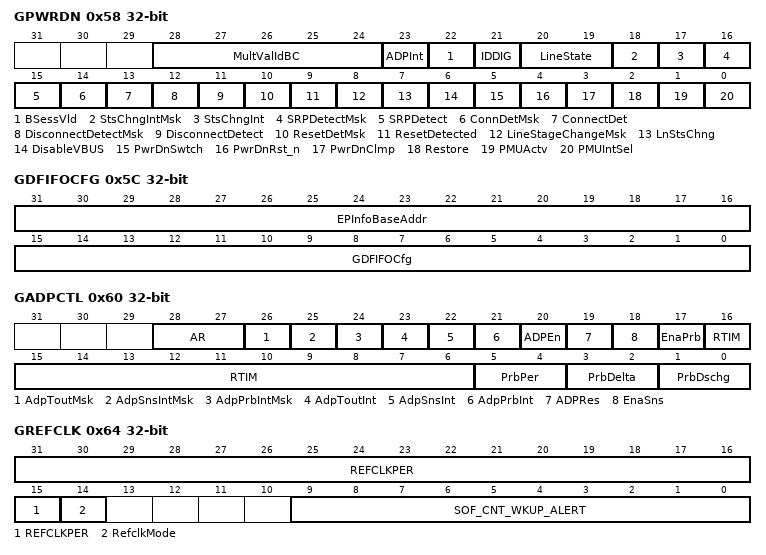
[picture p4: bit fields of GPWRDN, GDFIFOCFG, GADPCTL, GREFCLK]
0x58 GPWRDN — Global Power Down Register
  [28:24] MultValIdBC
    0=RID_0 (OTG device as B-device); 1=RID_C (OTG device as B-device, can connect); 2=RID_B (OTG device as B-device, cannot connect); 4=RID_A (OTG device as A-device); 8=RID_GND (ID_OTG pin is grounded); 16=RID_FLOAT (ID pull down when ID_OTG is floating); 17=RID_C_RID_FLOAT (OTG device as B-device, can connect, RID_C=1 and RID_FLOAT=1); 18=RID_B_RID_FLOAT (OTG device as B-device, cannot connect, RID_B=1 and RID_FLOAT=1); 12=RID_A_RID_GND (OTG device as A-device, RID_A=1 and RID_GND=1); 31=RID_1 (OTG device as A-device)
  [23] ADPInt — ADP Interrupt
    0=DISABLED (No ADP Event Interrupt); 1=ENABLED (ADP Event Interrupt)
  [22] BSessVld ro — B Session Valid
    0=NOTVALID (B_Valid is 0); 1=VALID (B_Valid is 1)
  [21] IDDIG ro — Status of signal IDDIG
    0=DISABLED (Host Mode); 1=ENABLED (Device Mode)
  [20:19] LineState ro
    0=LS1 (Linestate on USB: DM = 0, DP = 0); 1=LS2 (Linestate on USB: DM = 0, DP = 1); 2=LS3 (Linestate on USB: DM = 1, DP = 0); 3=LS4 (Linestate on USB: Not-defined)
  [18] StsChngIntMsk — Status Change Interrupt Mask
    0=NOMASK (No Status Change Interrupt Mask); 1=MASK (Mask for Status Change Interrupt)
  [17] StsChngInt — Status Change Interrupt
    0=DISABLED (No Status change); 1=ENABLED (Status change detected)
  [16] SRPDetectMsk — SRP Detect Mask
    0=NOMASK (No SRPDetect Interrupt Mask); 1=MASK (Mask for SRPDetect Interrupt)
  [15] SRPDetect
    0=DISABLED (SRP not detected); 1=ENABLED (SRP detected)
  [14] ConnDetMsk — Connect Detect Mask
    0=NOMASK (No ConnectDet Interrupt Mask); 1=MASK (Mask for ConnectDet Interrupt)
  [13] ConnectDet — Connect Detect
    0=DISABLED (Connect not detected); 1=ENABLED (Connect detected)
  [12] DisconnectDetectMsk — Disconnect Detect Mask
    0=NOMASK (No DisconnectDetect Interrupt Mask); 1=MASK (Mask for DisconnectDetect Interrupt)
  [11] DisconnectDetect
    0=DISABLED (Disconnect not detected); 1=ENABLED (Disconnect detected)
  [10] ResetDetMsk — Reset Detect Mask
    0=NOMASK (No ResetDetect Interrupt Mask); 1=MASK (Mask for ResetDetect Interrupt)
  [9] ResetDetected
    0=DISABLED (Reset not detected); 1=ENABLED (Reset detected)
  [8] LineStageChangeMsk — Line State Change Mask
    0=NOMASK (No LineStateChange Interrupt Mask); 1=MASK (Mask for LineStateChange Interrupt)
  [7] LnStsChng — Line State Change
    0=DISABLED (No LineState change on USB); 1=ENABLED (LineState change on USB)
  [6] DisableVBUS
    0=DISABLED (Not programmed to disable VBUS); 1=ENABLED (Programmed to disable VBUS)
  [5] PwrDnSwtch — Power Down Switch
    0=ON (The controller is in ON state); 1=OFF (The controller is in OFF state)
  [4] PwrDnRst_n — Power Down ResetN
    0=DISABLE (Reset the controller); 1=ENABLE (Normal operation)
  [3] PwrDnClmp — Power Down Clamp
    0=DISABLE (Disable PMU power clamp); 1=ENABLE (Enable PMU power clamp)
  [2] Restore
    0=DISABLE (Normal mode of operation); 1=ENABLE (Restore mode)
  [1] PMUActv — PMU Active
    0=DISABLE (Disable PMU module); 1=ENABLE (Enable PMU module)
  [0] PMUIntSel — PMU Interrupt Select
    0=DISABLE (Internal DWC_otg_core interrupt); 1=ENABLE (External DWC_otg_pmu interrupt)
0x5C GDFIFOCFG — Global DFIFO Configuration Register
  [31:16] EPInfoBaseAddr — Start address of the EP info controller
  [15:0] GDFIFOCfg — GDFIFO Configuration
0x60 GADPCTL — ADP Timer, Control and Status Register
  [28:27] AR — Access Request
    0=Request1 (Read/Write); 1=Request2 (Read); 2=Request3 (Write)
  [26] AdpToutMsk — ADP Timeout Interrupt Mask
    0=MASK (Mask ADP Timeout Interrupt); 1=NOMASK (Unmask ADP Timeout Interrupt)
  [25] AdpSnsIntMsk — ADP Sense Interrupt Mask
    0=MASK (Mask ADP Sense Interrupt); 1=NOMASK (Unmask ADP Sense Interrupt)
  [24] AdpPrbIntMsk — ADP Probe Interrupt Mask
    0=MASK (Mask ADP Probe Interrupt); 1=NOMASK (Unmask ADP Probe Interrupt)
  [23] AdpToutInt — ADP Timeout Interrupt
    0=NOTACTIVE; 1=ACTIVE (ADP Timeout Interrupt)
  [22] AdpSnsInt — ADP Sense Interrupt
    0=NOTACTIVE; 1=ACTIVE (ADP Sense Interrupt)
  [21] AdpPrbInt — ADP Probe Interrupt
    0=NOTACTIVE; 1=ACTIVE (ADP Probe Interrupt)
  [20] ADPEn — ADP Enable
    0=DISABLE (Not active); 1=ENABLE (Core does ADP Probing or Sensing)
  [19] ADPRes — ADP Reset
    0=DISABLE (Not active); 1=ENABLE (ADP controller is reset)
  [18] EnaSns — Enable Sense
    0=DISABLE (Not active); 1=ENABLE (Core performs sense operation)
  [17] EnaPrb — Enable Probe
    0=DISABLE (Not active); 1=ENABLE (Core performs probe operation)
  [16:6] RTIM ro — RAMP TIME
  [5:4] PrbPer — Probe Period
    0=TADP_PRB_0.6_0.9SEC (TadpPrd: 0.625 to 0.925 sec); 1=TADP_PRB_1.2_1.8SEC (TadpPrd: 1.25 to 1.85 sec); 2=TADP_PRB_1.9_2.6SEC (TadpPrd: 1.9 to 2.6 sec)
  [3:2] PrbDelta — Probe Delta
    0=1 cycle; 1=2 cycles; 2=3 cycles; 3=4 cycles
  [1:0] PrbDschg — Probe Discharge
    0=Probe Discharge time: 4 msec; 1=Probe Discharge time: 8 msec; 2=Probe Discharge time: 16 msec; 3=Probe Discharge time: 32 msec
0x64 GREFCLK — ref_clk Control Register
  [31:15] REFCLKPER — Period of ref_clk in terms of pico seconds
  [14] RefclkMode — Refclk Mode of Operation
    0=DISABLE (Controller uses phy_clk to run internal micro-frame timers); 1=ENABLE (Controller uses ref_clk to run internal micro-frame timers)
  [9:0] SOF_CNT_WKUP_ALERT — Number of SOF's for wakeup alert
0x68 GINTMSK2 — Interrupt Mask Register 2
  [0] WkUpAlertIntMsk — Remote WakeUp Alert Interrupt Mask
    0=MASK (Mask Remote WakeUp Alert Interrupt); 1=NOMASK (Unmask Remote WakeUp Alert Interrupt)
0x6C GINTSTS2 — Interrupt Register 2
  [0] WkUpAlertInt — Remote WakeUp Alert Interrupt
    0=INACTIVE (Not Active); 1=ACTIVE (Remote WakeUp Alert Interrupt detected)
0x100 HPTXFSIZ — Host Periodic Transmit FIFO Size Register
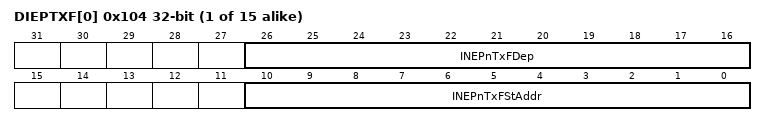
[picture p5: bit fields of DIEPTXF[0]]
{0x104+4i} DIEPTXF[{i}] (i=0..14) — Device IN Endpoint Transmit FIFO Size Register
  [26:16] INEPnTxFDep — IN Endpoint TxFIFO Depth (INEPnTxFDep)
  [10:0] INEPnTxFStAddr — IN Endpoint FIFOn Transmit RAM Start Address
